# S32R372 register map
Vendor: Freescale Semiconductor, Inc.; Series: Qorivva; File version: 1.6
Registers are 32-bit, read-write, reset 0x0 unless marked. A register's access mark holds for its fields unless they carry their own. Offsets are from the block's base; [hi:lo] are bit positions; {n}, {i} and the like mark numbered series.

## CTU
Base 0xFBC10000; register names take the prefix CTU_
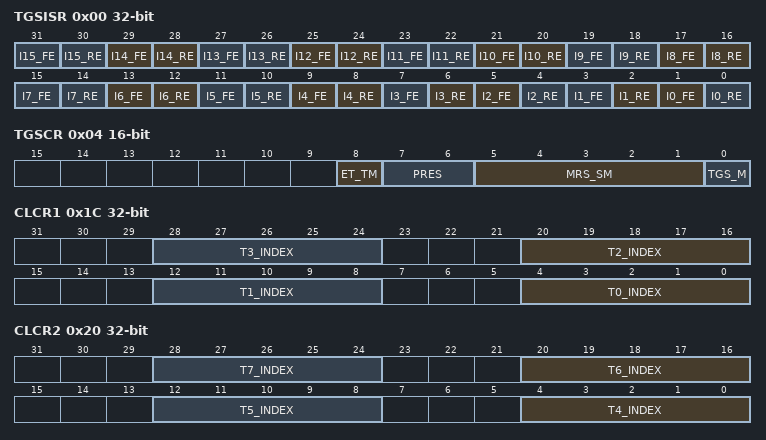
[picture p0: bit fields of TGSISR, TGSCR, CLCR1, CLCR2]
0x00 TGSISR — Trigger Generator Subunit Input Selection Register
  [all] fields
    0=Disabled; 1=Enabled
  [2n+1] I{n}_FE (n=0..15) — Input {n} Falling Edge Enable.
  [2n] I{n}_RE (n=4..15) — Input {n} Rising Edge Enable.
  [6] I3_RE — Input 3 Rising edge Enable
  [4] I2_RE — Input 2 Rising Edge Enable.
  [2] I1_RE — Input 1 Rising edge Enable
  [0] I0_RE — Input 0 Rising Edge Enable.
0x04 TGSCR 16-bit — Trigger Generator Subunit Control Register
  [8] ET_TM — Enable Toggle Mode for external Trigger.
    0=Pulse mode; 1=Toggle mode
  [7:6] PRES — Prescaler selection bits for TGS and SU. This prescaler is used by the TGS counter.
    {v}=Value is {v+1} (v=0..3)
  [5:1] MRS_SM — MRS Selection in Sequential Mode (5 bits to select one of the 32 inputs shown in the Trigger generator subunit input selection (TGSISR) register
  [0] TGS_M — Trigger Generator Subunit Mode.
    0=Triggered Mode; 1=Sequential Mode
{0x6+2i} T{i}CR (i=0..7) 16-bit — Trigger Compare Register
  [15:0] TCRV — Trigger Compare Register Value.
0x16 TGSCCR 16-bit — TGS Counter Compare Register
  [15:0] TGSCCV — TGS Counter Compare Value
0x18 TGSCRR 16-bit — TGS Counter Reload Register
  [15:0] TGSCRV — TGS Counter Reload Value
0x1C CLCR1 — Commands List Control Register 1
  [8n+4:8n] T{n}_INDEX (n=0..3) — Trigger {n} Commands List 1st command address
0x20 CLCR2 — Commands List Control Register 2
  [8n-28:8n-32] T{n}_INDEX (n=4..7) — Trigger {n} Commands List 1st command address
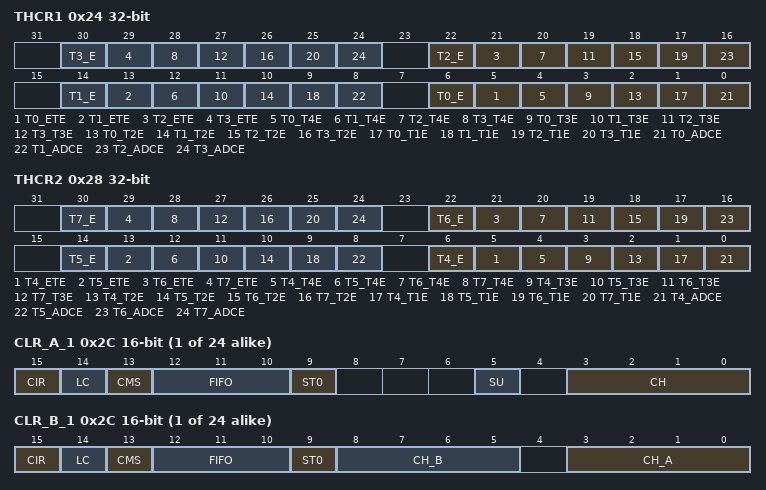
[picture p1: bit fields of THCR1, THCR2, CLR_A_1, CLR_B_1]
0x24 THCR1 — Trigger Handler Control Register 1
  [all] fields
    0=Disabled; 1=Enabled
  [8n+6] T{n}_E (n=0..3) — Trigger {n} Enable.
  [8n+5] T{n}_ETE (n=0..3) — Trigger {n} External Trigger output Enable.
  [8n+4] T{n}_T4E (n=0..3) — Trigger {n} ETIMER4_TRG output Enable.
  [8n+3] T{n}_T3E (n=0..3) — Trigger {n} ETIMER3_TRG output Enable.
  [8n+2] T{n}_T2E (n=0..3) — Trigger {n} ETIMER2_TRG output Enable.
  [8n+1] T{n}_T1E (n=0..3) — Trigger {n} ETIMER1_TRG output Enable.
  [8n] T{n}_ADCE (n=0..3) — Trigger {n} ADC command output Enable.
0x28 THCR2 — Trigger Handler Control Register 2
  [all] fields
    0=Disabled; 1=Enabled
  [8n-26] T{n}_E (n=4..7) — Trigger {n} Enable.
  [8n-27] T{n}_ETE (n=4..7) — Trigger {n} External Trigger output Enable.
  [8n-28] T{n}_T4E (n=4..7) — Trigger {n} ETIMER4_TRG output Enable.
  [8n-29] T{n}_T3E (n=4..7) — Trigger {n} ETIMER3_TRG output Enable.
  [8n-30] T{n}_T2E (n=4..7) — Trigger {n} ETIMER2_TRG output Enable.
  [8n-31] T{n}_T1E (n=4..7) — Trigger {n} ETIMER1_TRG output Enable.
  [8n-32] T{n}_ADCE (n=4..7) — Trigger {n} ADC command output Enable.
{0x2A+2i} CLR_A_{i} (i=1..24) 16-bit (CTU view) — Commands List Register A for ADC single-conversion mode commands
  [15] CIR — Command execution Interrupt Request enable bit.
    0=Disabled; 1=Enabled
  [14] LC — Last Command bit.
    0=Not last; 1=Last
  [13] CMS — Conversion Mode Selection. Must be 0 in this register format.
    0=Single conversion mode; 1=Dual conversion mode
  [12:10] FIFO — FIFO used for ADC Port A / Port B.
    0=FIFO_0 select; 7=FIFO_7 select
  [9] ST0 — Self Test mode control 0. Must be 0 in this register format.
  [5] SU — ADC Port A / Port B selection.
    0=ADC Port A selected; 1=ADC Port B selected
  [3:0] CH — ADC Port channel number.
{0x2A+2i} CLR_B_{i} (i=1..24) 16-bit (CTU view) — Command List Register B for ADC dual-conversion mode commands
  [15] CIR — Command execution Interrupt Request enable bit.
    0=Disabled; 1=Enabled
  [14] LC — Last Command bit.
    0=Not last; 1=Last
  [13] CMS — Conversion Mode Selection. Must be 1 in this register format.
    0=Single conversion mode; 1=Dual conversion mode
  [12:10] FIFO — FIFO used for ADC Port A / Port B.
    0=FIFO_0 select; 7=FIFO_7 select
  [9] ST0 ro — Sel-Test mode control 0. Must be 0 in this register format.
  [8:5] CH_B — ADC Port B channel number.
  [3:0] CH_A — ADC Port A channel number.
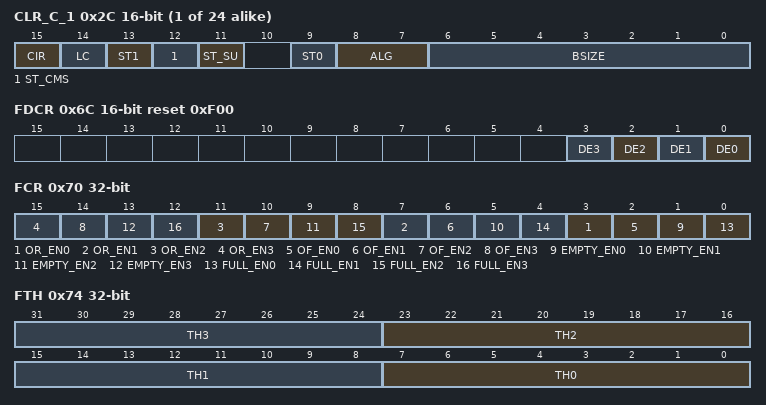
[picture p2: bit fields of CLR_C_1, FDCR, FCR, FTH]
{0x2A+2i} CLR_C_{i} (i=1..24) 16-bit (CTU view) — Command List Register C for self-test commands
  [15] CIR — Command Execution Interrupt Request enable bit (this bit has no influence in this mode)
    0=Disabled; 1=Enabled
  [14] LC — Last command bit.
    0=Not last; 1=Last
  [13] ST1 — Self Test command control 1. ST1 must be 0 for a self test command.
  [12] ST_CMS — Conversion Mode Selection for Self Test command.
    0=Single Conversion Mode; 1=Dual Conversion Mode
  [11] ST_SU — Self Test Selection Unit bit. Usable only if ST_CMS is 0.
    0=ADC Port A; 1=ADC Port B
  [9] ST0 — Self Test command control 0. ST0 must 1 in this register format.
  [8:7] ALG — Algorithm scheduled:
    0=Algorithm S; 2=Algorithm C; 3=Full algorithm (S + C)
  [6:0] BSIZE — Burst size of the algorithm iteration.
    0=Single step execution; 127=512 step execution with one trigger
0x6C FDCR 16-bit reset 0xF00 — FIFO DMA Control Register
  [all] fields
    0=Disabled; 1=Enabled
  [n] DE{n} (n=0..3) — FIFO {n} DMA enable.
0x70 FCR — FIFO Control Register
  [all] fields
    0=Disabled; 1=Enabled
  [4n+3] OR_EN{n} (n=0..3) — FIFO {n} Overrun interrupt enable.
  [4n+2] OF_EN{n} (n=0..3) — FIFO {n} threshold Overflow interrupt enable.
  [4n+1] EMPTY_EN{n} (n=0..3) — FIFO {n} Empty interrupt enable.
  [4n] FULL_EN{n} (n=0..3) — FIFO {n} Full interrupt enable.
0x74 FTH — FIFO Threshold Register
  [8n+7:8n] TH{n} (n=0..3) — FIFO {n} Threshold.
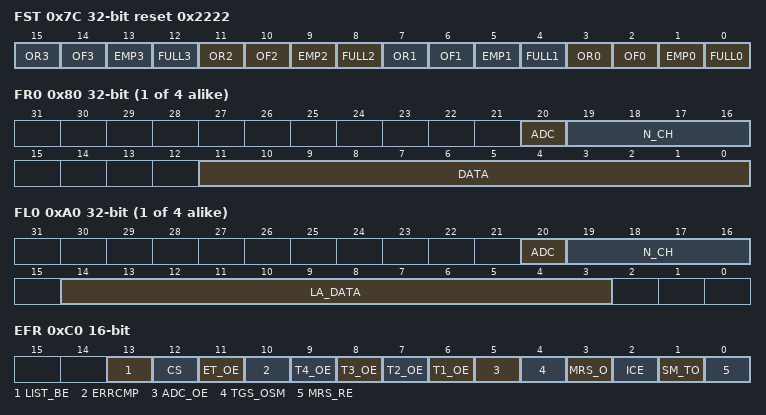
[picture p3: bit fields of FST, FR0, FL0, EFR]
0x7C FST reset 0x2222 — FIFO Status Register
  [all] fields
    0=Interrupt has not occurred; 1=Interrupt has occurred
  [4n+3] OR{n} (n=0..3) — FIFO {n} Overrun interrupt flag. It is cleared if 1 is written to this bit location.
  [4n+2] OF{n} ro (n=0..3) — FIFO {n} threshold Overflow interrupt flag.
  [4n+1] EMP{n} ro (n=0..3) — FIFO {n} Empty interrupt flag.
  [4n] FULL{n} ro (n=0..3) — FIFO {n} Full interrupt flag.
{0x80+4i} FR{i} (i=0..3) ro — FIFO Right Aligned Data Register
  [20] ADC — This bit indicates from which ADC Port the value in the DATA field corresponds to.
    0=Data coming from ADC Port B; 1=Data coming from ADC Port A
  [19:16] N_CH — Number of the channel that DATA field corresponds to.
  [11:0] DATA — Data of stored channel.
{0xA0+4i} FL{i} (i=0..3) ro — FIFO Signed Left Aligned Data Register
  [20] ADC — This bit indicates from which ADC Port the value in the DATA field corresponds to.
    0=Data coming from ADC Port B; 1=Data coming from ADC Port A
  [19:16] N_CH — Number of the channel that DATA field corresponds to.
  [14:3] LA_DATA — Data of stored channel.
0xC0 EFR 16-bit — Error Flag Register
  [13] LIST_BE — List Busy Error
    0=No error; 1=Error
  [12] CS — Self test Counter Status
    0=All the counters are at reset value, thus none of the self-test algorithm are executing; 1=One of the counters used in self test mode is not in the reset state, thus self-test is in progress
  [11] ET_OE — External Trigger generation Overrun Error
    0=No error; 1=Error
  [10] ERRCMP — Error Compare
    0=No match; 1=Match
  [n+5] T{n}_OE (n=1..4) — Timer {n} trigger generation Overrun Error
    0=No error; 1=Error
  [5] ADC_OE — ADC command generation Overrun Error
    0=No Error; 1=Error
  [4] TGS_OSM — The TGS Overrun in Sequential Mode
    0=No overrun; 1=Overrun
  [3] MRS_O — Master Reload Signal Overrun
    0=No overrun; 1=Overrun
  [2] ICE — Invalid Command Error
    0=No error; 1=Error
  [1] SM_TO — Trigger Overrun (more than 8 ES) in TGS Sequential Mode
    0=No overrun; 1=Overrun
  [0] MRS_RE — Master Reload Signal Reload Error
    0=No error; 1=Error
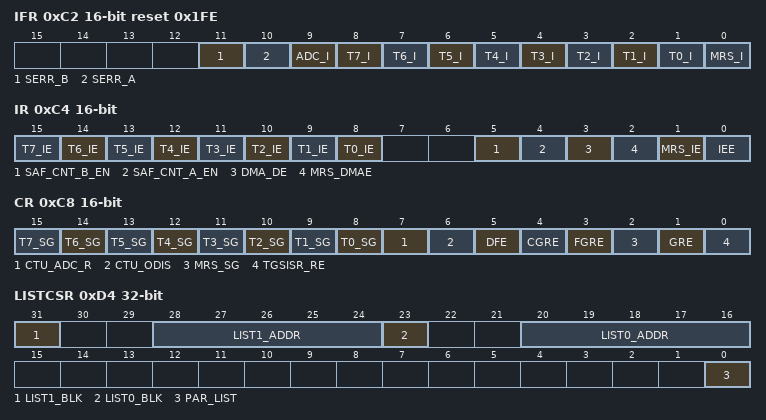
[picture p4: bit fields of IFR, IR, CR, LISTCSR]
0xC2 IFR 16-bit reset 0x1FE — Interrupt Flag Register
  [11] SERR_B — If this bit is set, it means that the time between the start of a conversion and the end of that conversion is out of the expected range which is defined by the EXPBR and CNTRNGR registers
  [10] SERR_A — If this bit is set, it means that the time between the start of a conversion and the end of that conversion is out of the expected range defined by the EXPAR and CNTRNGR registers
  [9] ADC_I — ADC command interrupt flag is set when a new command is issued
  [n+1] T{n}_I (n=0..7) — Trigger {n} interrupt flag is set when the corresponding trigger is issued
  [0] MRS_I — MRS Interrupt flag is set when the Master Reload Signal occurs
0xC4 IR 16-bit — Interrupt/DMA Register
  [n+8] T{n}_IE (n=0..7) — Trigger {n} Interrupt Enable.
    0=Disabled; 1=Enabled
  [5] SAF_CNT_B_EN — Enable the ADC Port B counter to check the conversion time.
    0=Disabled; 1=Enabled
  [4] SAF_CNT_A_EN — Enable the ADC Port A counter to check the conversion time.
    0=Disabled; 1=Enabled
  [3] DMA_DE — If this bit is set, a dma done acts as a write '1' in the GRE bit.
  [2] MRS_DMAE — If GRE bit is set, DMA request is issued on MRS occurrence.
  [1] MRS_IE — MRS Interrupt Enable.
    0=Disabled; 1=Enabled
  [0] IEE — Interrupt Error Enable.
    0=Disabled; 1=Enabled
0xC6 COTR 16-bit — Control ON Time Register
  [7:0] COTGT — Control ON-Time and Guard Time for external trigger
0xC8 CR 16-bit — Control Register
  [n+8] T{n}_SG wo (n=0..7) — Trigger {n} Software Generated.
    0=S/W not generated; 1=S/W generated
  [7] CTU_ADC_R wo — CTU command list control state machine Reset
  [6] CTU_ODIS — CTU Output Disable.
    0=Enabled; 1=Disabled
  [5] DFE — Digital Filter Enable.
    0=Disabled; 1=Enabled
  [4] CGRE wo — Clear GRE to 0.
  [3] FGRE ro — Flag GRE. See Reload mechanism for more details.
  [2] MRS_SG wo — MRS Software Generated.
    0=S/W not generated; 1=S/W generated
  [1] GRE — General Reload Enable. See Reload mechanism for more details.
    0=Disabled; 1=Enabled
  [0] TGSISR_RE — TGS Input Selection Register Reload Enable
0xCA DFR 16-bit — Digital Filter Register
  [7:0] FILTER_N — Digital Filter value
    0=Filter is in bypass; 1=In all combinations of FILTERN_N greater than 0, the filter is not in bypass; 255=In all combinations of FILTERN_N greater than 0, the filter is not in bypass
0xCC EXPAR 16-bit reset 0xFFFF — Expected Value A Register
  [15:0] EXPA — This value is the expected number of system clock cycles needed by ADC Port A to complete a conversion.
0xCE EXPBR 16-bit reset 0xFFFF — Expected Value B Register
  [15:0] EXPB — This value is the expected number of system clock cycles needed by ADC Port B to complete a conversion.
0xD0 CNTRNGR 16-bit — Counter Range Register
  [7:0] CNTRNG — If set, the bits in this field mask out the equivalent bits of the expected values EXP_A and EXP_B
0xD4 LISTCSR — List Control/Status Register
  [31] LIST1_BLK ro — List 1 Blocked flag
  [28:24] LIST1_ADDR ro — List Address 1
  [23] LIST0_BLK ro — List 0 Blocked flag
  [20:16] LIST0_ADDR ro — List Address 0. Indicates the command address being executed when LIST_BE flag in EFR register was set.
  [0] PAR_LIST — Parallel mode List. This bit selects the parallel mode for the list execution.
    0=List is executed in streaming mode; 1=List is executed in parallel mode
